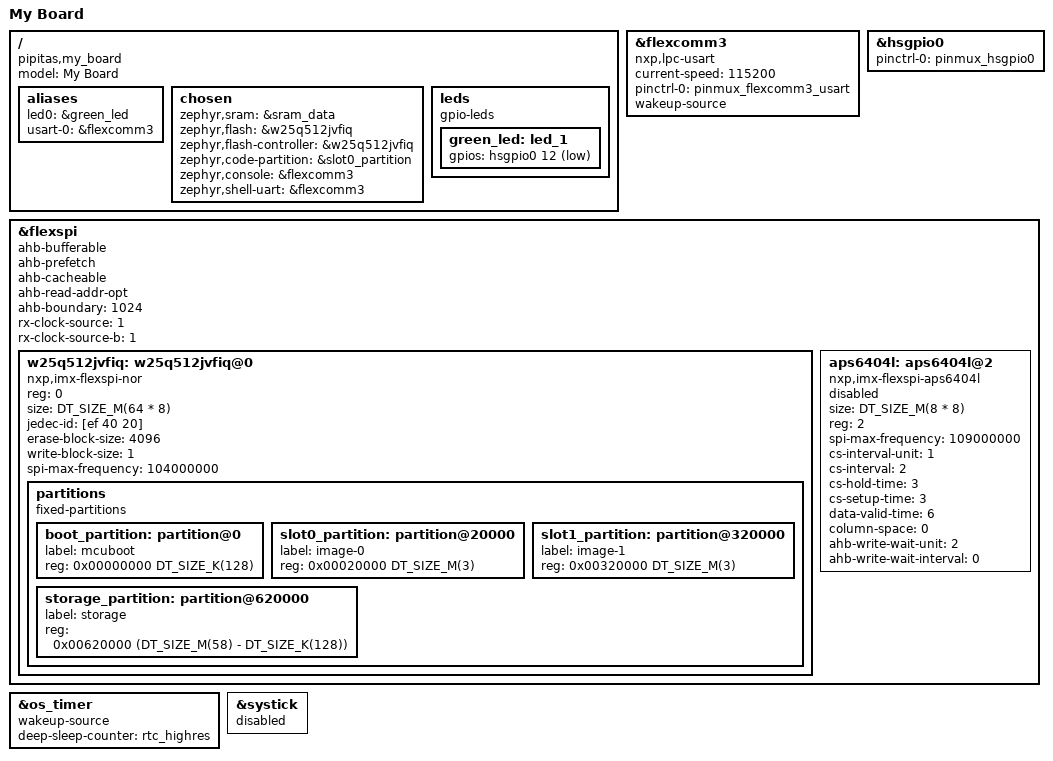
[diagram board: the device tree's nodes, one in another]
#include "frdm_rw612-pinctrl.dtsi"
#include <zephyr/dt-bindings/input/input-event-codes.h>

/ {
	model = "My Board";
	compatible = "pipitas,my_board";

	aliases {
		led0 = &green_led;
		usart-0 = &flexcomm3;
	};

	chosen {
		zephyr,sram = &sram_data;
		zephyr,flash = &w25q512jvfiq;
		zephyr,flash-controller = &w25q512jvfiq;
		zephyr,code-partition = &slot0_partition;
		zephyr,console = &flexcomm3;
		zephyr,shell-uart = &flexcomm3;
	};

	leds {
		compatible = "gpio-leds";
		green_led: led_1 {
			gpios = <&hsgpio0 12 GPIO_ACTIVE_LOW>;
		};
	};
};

&flexcomm3 {
	compatible = "nxp,lpc-usart";
	status = "okay";
	current-speed = <115200>;
	pinctrl-0 = <&pinmux_flexcomm3_usart>;
	pinctrl-names = "default";
	wakeup-source;
};

&hsgpio0 {
	status = "okay";
	pinctrl-0 = <&pinmux_hsgpio0>;
	pinctrl-names = "default";
};

&flexspi {
	status = "okay";
	ahb-bufferable;
	ahb-prefetch;
	ahb-cacheable;
	ahb-read-addr-opt;
	ahb-boundary = "1024";
	rx-clock-source = <1>;
	rx-clock-source-b = <1>;
	/* Winbond external flash */
	w25q512jvfiq: w25q512jvfiq@0 {
		compatible = "nxp,imx-flexspi-nor";
		reg = <0>;
		size = <DT_SIZE_M(64 * 8)>;
		status = "okay";
		jedec-id = [ef 40 20];
		erase-block-size = <4096>;
		write-block-size = <1>;
		spi-max-frequency = <104000000>;

		partitions {
			compatible = "fixed-partitions";
			#address-cells = <1>;
			#size-cells = <1>;

			/*
			 * Partition sizes must be aligned
			 * to the flash memory sector size of 4KB.
			 */
			boot_partition: partition@0 {
				label = "mcuboot";
				reg = <0x00000000 DT_SIZE_K(128)>;
			};
			slot0_partition: partition@20000 {
				label = "image-0";
				reg = <0x00020000 DT_SIZE_M(3)>;
			};
			slot1_partition: partition@320000 {
				label = "image-1";
				reg = <0x00320000 DT_SIZE_M(3)>;
			};
			storage_partition: partition@620000 {
				label = "storage";
				reg = <0x00620000 (DT_SIZE_M(58) - DT_SIZE_K(128))>;
			};
		};
	};
	aps6404l: aps6404l@2 {
			compatible = "nxp,imx-flexspi-aps6404l";
			/* APS6404L is 8MB, 64MBit pSRAM */
			size = <DT_SIZE_M(8 * 8)>;
			reg = <2>;
			spi-max-frequency = <109000000>;
			/* PSRAM cannot be enabled while board is in default XIP
			 * configuration, as it will conflict with flash chip.
			 */
			status = "disabled";
			cs-interval-unit = <1>;
			cs-interval = <2>;
			cs-hold-time = <3>;
			cs-setup-time = <3>;
			data-valid-time = <6>;
			column-space = <0>;
			ahb-write-wait-unit = <2>;
			ahb-write-wait-interval = <0>;
	};
};

/* OS Timer is the wakeup source for PM mode 2 */
&os_timer {
	status = "okay";
	wakeup-source;
	deep-sleep-counter = <&rtc_highres>;
};

&systick {
	status = "disabled";
};
